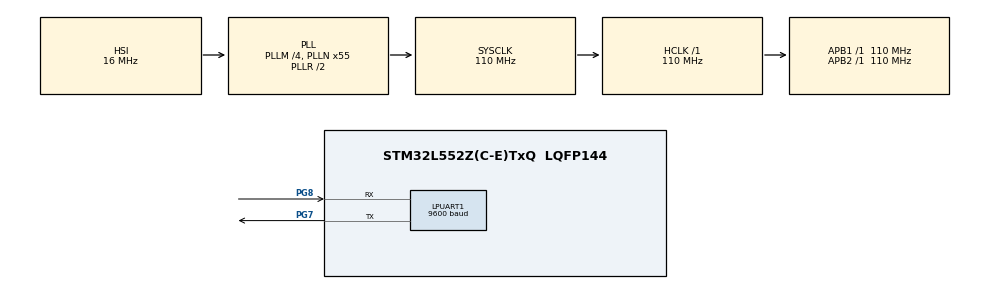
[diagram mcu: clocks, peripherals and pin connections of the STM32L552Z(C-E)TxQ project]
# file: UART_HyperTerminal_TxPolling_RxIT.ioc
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LPUART1.BaudRate=9600
LPUART1.DMADisableonRxErrorParam-Asynchronous=UART_ADVFEATURE_DMA_ENABLEONRXERROR
LPUART1.DataInvertParam-Asynchronous=UART_ADVFEATURE_DATAINV_DISABLE
LPUART1.MSBFirstParam-Asynchronous=UART_ADVFEATURE_MSBFIRST_DISABLE
LPUART1.Mode-Asynchronous=UART_MODE_TX_RX
LPUART1.OneBitSampling=UART_ONE_BIT_SAMPLE_DISABLE
LPUART1.OverrunDisableParam-Asynchronous=UART_ADVFEATURE_OVERRUN_ENABLE
LPUART1.Parity-Asynchronous=UART_PARITY_ODD
LPUART1.RXFIFOThreshold-Asynchronous=UART_RXFIFO_THRESHOLD_1_8
LPUART1.RxPinLevelInvertParam-Asynchronous=UART_ADVFEATURE_RXINV_DISABLE
LPUART1.StopBits-Asynchronous=UART_STOPBITS_1
LPUART1.SwapParam-Asynchronous=UART_ADVFEATURE_SWAP_DISABLE
LPUART1.TXFIFOThreshold-Asynchronous=UART_TXFIFO_THRESHOLD_1_8
LPUART1.TxPinLevelInvertParam-Asynchronous=UART_ADVFEATURE_TXINV_DISABLE
LPUART1.WordLength=UART_WORDLENGTH_8B
Mcu.Family=STM32L5
Mcu.Name=STM32L552Z(C-E)TxQ
Mcu.Package=LQFP144
NVIC.LPUART1_IRQn=true\:0\:0\:false\:false\:true\:true\:true\:true
NVIC.PriorityGroup=NVIC_PRIORITYGROUP_3
PG7.Mode=Asynchronous
PG7.Signal=LPUART1_TX
PG8.Mode=Asynchronous
PG8.Signal=LPUART1_RX
ProjectManager.HeapSize=0x200
ProjectManager.StackSize=0x400
ProjectManager.TargetToolchain=EWARM V8.32
RCC.ADCFreq_Value=48000000
RCC.AHBFreq_Value=110000000
RCC.APB1Freq_Value=110000000
RCC.APB1TimFreq_Value=110000000
RCC.APB2Freq_Value=110000000
RCC.APB2TimFreq_Value=110000000
RCC.CortexFreq_Value=110000000
RCC.DATA_CACHE_ENABLE=0
RCC.HCLKFreq_Value=110000000
RCC.HSE_VALUE=16000000
RCC.HSI48_VALUE=48000000
RCC.HSI_VALUE=16000000
RCC.INSTRUCTION_CACHE_ENABLE=0
RCC.LPUART1CLockSelectionVirtual=RCC_LPUART1CLKSOURCE_HSI
RCC.LSE_VALUE=32768
RCC.MSI_VALUE=4000000
RCC.PLLM=4
RCC.PLLN=55
RCC.PLLSAI1N=24
RCC.PLLSourceVirtual=RCC_PLLSOURCE_HSI
RCC.RTCClockSelection=RCC_RTCCLKSOURCE_LSE
RCC.SYSCLKFreq_VALUE=110000000
RCC.SYSCLKSource=RCC_SYSCLKSOURCE_PLLCLK
RCC.USBFreq_Value=48000000
RCC.VCOOutputFreq_Value=220000000
VP_ICACHE_VS_ICACHE.Mode=DirectMappedCache
VP_PWR_VS_DBSignals.Mode=DisableDeadBatterySignals
board=custom

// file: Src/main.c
/* USER CODE BEGIN Header */
/**
  ******************************************************************************
  * @file    UART/UART_HyperTerminal_TxPolling_RxIT/Src/main.c
  * @author  MCD Application Team
  * @brief   This sample code shows how to use UART HAL and LL APIs to transmit
  *          data in polling mode while receiving data in Interrupt mode, by mixing
  *          use of LL and HAL APIs;
  *          HAL driver is used to perform UART configuration,
  *          then TX transfer procedure is based on HAL APIs use (polling)
  *               RX transfer procedure is based on LL APIs use (IT)
  ******************************************************************************
  * @attention
  *
  * Copyright (c) 2019 STMicroelectronics.
  * All rights reserved.
  *
  * This software is licensed under terms that can be found in the LICENSE file
  * in the root directory of this software component.
  * If no LICENSE file comes with this software, it is provided AS-IS.
  *
  ******************************************************************************
  */
/* USER CODE END Header */
#include "main.h"

UART_HandleTypeDef hlpuart1;

/* USER CODE BEGIN PV */

/* Buffer used for transmission */
uint8_t aTxStartMessage[] = "\n\r ****UART-Hyperterminal TXRX communication (TX based on HAL polling API, RX based on IT LL API) ****\n\r Enter characters using keyboard ...\n\r";
uint8_t ubSizeToSend = sizeof(aTxStartMessage);

/* Buffer used for reception */
uint8_t aRXBufferA[RX_BUFFER_SIZE];
uint8_t aRXBufferB[RX_BUFFER_SIZE];
__IO uint32_t uwNbReceivedChars = 0;
__IO uint32_t uwBufferReadyIndication = 0;
uint8_t *pBufferReadyForUser;
uint8_t *pBufferReadyForReception;

/* USER CODE END PV */

void SystemClock_Config(void);
static void MX_GPIO_Init(void);
static void MX_ICACHE_Init(void);
static void MX_LPUART1_UART_Init(void);

int main(void)
{
  /* USER CODE BEGIN 1 */
/* STM32L5xx HAL library initialization:
       - Systick timer is configured by default as source of time base, but user
         can eventually implement his proper time base source (a general purpose
         timer for example or other time source), keeping in mind that Time base
         duration should be kept 1ms since PPP_TIMEOUT_VALUEs are defined and
         handled in milliseconds basis.
       - Set NVIC Group Priority to 3
       - Low Level Initialization
     */
  /* USER CODE END 1 */

  /* MCU Configuration--------------------------------------------------------*/

  /* Reset of all peripherals, Initializes the Flash interface and the Systick. */
  HAL_Init();

  /* USER CODE BEGIN Init */
  /* Configure leds */
  BSP_LED_Init(LED1);
  BSP_LED_Init(LED2);
  BSP_LED_Init(LED3);

  /* USER CODE END Init */

  /* Configure the system clock */
  SystemClock_Config();

  /* Initialize all configured peripherals */
  MX_GPIO_Init();
  MX_ICACHE_Init();
  MX_LPUART1_UART_Init();
  /* USER CODE BEGIN 2 */

  /*## Configure UART peripheral for reception process (using LL) ##########*/
  /* Initializes Buffer swap mechanism :
     2 physical buffers aRXBufferA and aRXBufferB (RX_BUFFER_SIZE length)
     Any data received will be stored in active buffer : the number max of
     data received is RX_BUFFER_SIZE */
  pBufferReadyForReception = aRXBufferA;
  pBufferReadyForUser      = aRXBufferB;
  uwNbReceivedChars = 0;
  uwBufferReadyIndication = 0;
  /* Enable RXNE and Error interrupts */
  LL_USART_EnableIT_RXNE(LPUART1);
  LL_USART_EnableIT_ERROR(LPUART1);

  /*## Start the transmission process (using HAL Polling mode) #############*/
  /* In main loop, Tx buffer is sent every 0.5 sec.
     As soon as RX buffer is detected as full, received bytes are echoed on TX line to PC com port */
  /* USER CODE END 2 */

  /* Infinite loop */
  /* USER CODE BEGIN WHILE */
  while (1)
  {

    /* USART IRQ handler is not anymore routed to HAL_UART_IRQHandler() function
       and is now based on LL API functions use.
       Therefore, use of HAL IT based services is no more possible : use TX HAL polling services */
    if(HAL_UART_Transmit(&hlpuart1, (uint8_t*)aTxStartMessage, ubSizeToSend, 1000)!= HAL_OK)
    {
      /* Transfer error in transmission process */
      Error_Handler();
    }

    /* Checks if Buffer full indication has been set */
    if (uwBufferReadyIndication != 0)
    {
      /* Reset indication */
      uwBufferReadyIndication = 0;

      /* USART IRQ handler is not anymore routed to HAL_UART_IRQHandler() function
         and is now based on LL API functions use.
         Therefore, use of HAL IT based services is no more possible : use TX HAL polling services */
      if(HAL_UART_Transmit(&hlpuart1, (uint8_t*)pBufferReadyForUser, RX_BUFFER_SIZE, 1000)!= HAL_OK)
      {
        /* Transfer error in transmission process */
        Error_Handler();
      }

      /* Toggle LED1 */
      BSP_LED_Toggle(LED1);
    }

    /* Manage temporisation between TX buffer sendings */
    HAL_Delay(500);

    /* USER CODE END WHILE */

  }
}

void SystemClock_Config(void)
{
  RCC_OscInitTypeDef RCC_OscInitStruct = {0};
  RCC_ClkInitTypeDef RCC_ClkInitStruct = {0};

  /** Configure the main internal regulator output voltage
  */
  if (HAL_PWREx_ControlVoltageScaling(PWR_REGULATOR_VOLTAGE_SCALE0) != HAL_OK)
  {
    Error_Handler();
  }

  /** Initializes the RCC Oscillators according to the specified parameters
  * in the RCC_OscInitTypeDef structure.
  */
  RCC_OscInitStruct.OscillatorType = RCC_OSCILLATORTYPE_HSI;
  RCC_OscInitStruct.HSIState = RCC_HSI_ON;
  RCC_OscInitStruct.HSICalibrationValue = RCC_HSICALIBRATION_DEFAULT;
  RCC_OscInitStruct.PLL.PLLState = RCC_PLL_ON;
  RCC_OscInitStruct.PLL.PLLSource = RCC_PLLSOURCE_HSI;
  RCC_OscInitStruct.PLL.PLLM = 4;
  RCC_OscInitStruct.PLL.PLLN = 55;
  RCC_OscInitStruct.PLL.PLLP = RCC_PLLP_DIV7;
  RCC_OscInitStruct.PLL.PLLQ = RCC_PLLQ_DIV2;
  RCC_OscInitStruct.PLL.PLLR = RCC_PLLR_DIV2;
  if (HAL_RCC_OscConfig(&RCC_OscInitStruct) != HAL_OK)
  {
    Error_Handler();
  }

  /** Initializes the CPU, AHB and APB buses clocks
  */
  RCC_ClkInitStruct.ClockType = RCC_CLOCKTYPE_HCLK|RCC_CLOCKTYPE_SYSCLK
                              |RCC_CLOCKTYPE_PCLK1|RCC_CLOCKTYPE_PCLK2;
  RCC_ClkInitStruct.SYSCLKSource = RCC_SYSCLKSOURCE_PLLCLK;
  RCC_ClkInitStruct.AHBCLKDivider = RCC_SYSCLK_DIV1;
  RCC_ClkInitStruct.APB1CLKDivider = RCC_HCLK_DIV1;
  RCC_ClkInitStruct.APB2CLKDivider = RCC_HCLK_DIV1;

  if (HAL_RCC_ClockConfig(&RCC_ClkInitStruct, FLASH_LATENCY_5) != HAL_OK)
  {
    Error_Handler();
  }
}

static void MX_ICACHE_Init(void)
{

  /** Enable instruction cache in 1-way (direct mapped cache)
  */
  if (HAL_ICACHE_ConfigAssociativityMode(ICACHE_1WAY) != HAL_OK)
  {
    Error_Handler();
  }
  if (HAL_ICACHE_Enable() != HAL_OK)
  {
    Error_Handler();
  }

}

static void MX_LPUART1_UART_Init(void)
{

  hlpuart1.Instance = LPUART1;
  hlpuart1.Init.BaudRate = 9600;
  hlpuart1.Init.WordLength = UART_WORDLENGTH_8B;
  hlpuart1.Init.StopBits = UART_STOPBITS_1;
  hlpuart1.Init.Parity = UART_PARITY_ODD;
  hlpuart1.Init.Mode = UART_MODE_TX_RX;
  hlpuart1.Init.HwFlowCtl = UART_HWCONTROL_NONE;
  hlpuart1.Init.OneBitSampling = UART_ONE_BIT_SAMPLE_DISABLE;
  hlpuart1.Init.ClockPrescaler = UART_PRESCALER_DIV1;
  hlpuart1.AdvancedInit.AdvFeatureInit = UART_ADVFEATURE_NO_INIT;
  hlpuart1.FifoMode = UART_FIFOMODE_DISABLE;
  if (HAL_UART_Init(&hlpuart1) != HAL_OK)
  {
    Error_Handler();
  }
  if (HAL_UARTEx_SetTxFifoThreshold(&hlpuart1, UART_TXFIFO_THRESHOLD_1_8) != HAL_OK)
  {
    Error_Handler();
  }
  if (HAL_UARTEx_SetRxFifoThreshold(&hlpuart1, UART_RXFIFO_THRESHOLD_1_8) != HAL_OK)
  {
    Error_Handler();
  }
  if (HAL_UARTEx_DisableFifoMode(&hlpuart1) != HAL_OK)
  {
    Error_Handler();
  }

}

static void MX_GPIO_Init(void)
{

  /* GPIO Ports Clock Enable */
  __HAL_RCC_GPIOG_CLK_ENABLE();
  HAL_PWREx_EnableVddIO2();

}

/* USER CODE BEGIN 4 */

/**
  * @brief  Rx Transfer completed callback
  * @note   This example shows a simple way to report end of IT Rx transfer, and
  *         you can add your own implementation.
  * @retval None
  */
void UART_CharReception_Callback(void)
{
uint8_t *ptemp;

  /* Read Received character. RXNE flag is cleared by reading of RDR register */
  pBufferReadyForReception[uwNbReceivedChars++] = LL_USART_ReceiveData8(LPUART1);

  /* Checks if Buffer full indication has to be set */
  if (uwNbReceivedChars >= RX_BUFFER_SIZE)
  {
    /* Set Buffer swap indication */
    uwBufferReadyIndication = 1;

    /* Swap buffers for next bytes to be received */
    ptemp = pBufferReadyForUser;
    pBufferReadyForUser = pBufferReadyForReception;
    pBufferReadyForReception = ptemp;
    uwNbReceivedChars = 0;
  }
}

/**
  * @brief  UART error callbacks
  * @note   This example shows a simple way to report transfer error, and you can
  *         add your own implementation.
  * @retval None
  */
void UART_Error_Callback(void)
{
  __IO uint32_t isr_reg;

  /* Disable USARTx_IRQn */
  NVIC_DisableIRQ(LPUART1_IRQn);

  /* Error handling example :
    - Read USART ISR register to identify flag that leads to IT raising
    - Perform corresponding error handling treatment according to flag
  */
  isr_reg = LL_USART_ReadReg(LPUART1, ISR);
  if (isr_reg & LL_USART_ISR_NE)
  {
    /* Turn LED3 on: Transfer error in reception/transmission process */
    BSP_LED_On(LED3);
  }
  else
  {
    /* Turn LED3 on: Transfer error in reception/transmission process */
    BSP_LED_On(LED3);
  }
}

/* USER CODE END 4 */

void Error_Handler(void)
{
  /* USER CODE BEGIN Error_Handler_Debug */
  /* User can add his own implementation to report the HAL error return state */
  /* Toggle LED3 for error */
  while(1)
  {
    BSP_LED_Toggle(LED3);
    HAL_Delay(1000);
  }
  /* USER CODE END Error_Handler_Debug */
}

#ifdef  USE_FULL_ASSERT
/**
  * @brief  Reports the name of the source file and the source line number
  *         where the assert_param error has occurred.
  * @param  file: pointer to the source file name
  * @param  line: assert_param error line source number
  * @retval None
  */
void assert_failed(uint8_t *file, uint32_t line)
{
  /* USER CODE BEGIN 6 */
  /* User can add his own implementation to report the file name and line number,
     ex: printf("Wrong parameters value: file %s on line %d\r\n", file, line) */
  /* Infinite loop */
  while (1)
  {}
  /* USER CODE END 6 */
}
#endif /* USE_FULL_ASSERT */
